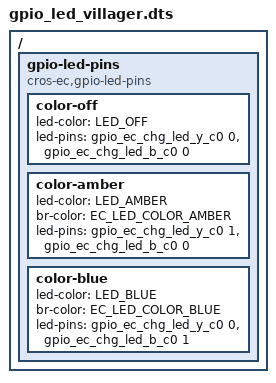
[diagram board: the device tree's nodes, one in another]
/* Copyright 2022 The Chromium OS Authors. All rights reserved.
 * Use of this source code is governed by a BSD-style license that can be
 * found in the LICENSE file.
 */

/ {
	gpio-led-pins {
		compatible = "cros-ec,gpio-led-pins";

		color-off {
			led-color = "LED_OFF";
			led-pins = <&gpio_ec_chg_led_y_c0 0>,
				   <&gpio_ec_chg_led_b_c0 0>;
		};

		color-amber {
			led-color = "LED_AMBER";
			br-color = "EC_LED_COLOR_AMBER";
			led-pins = <&gpio_ec_chg_led_y_c0 1>,
				   <&gpio_ec_chg_led_b_c0 0>;
		};

		color-blue {
			led-color = "LED_BLUE";
			br-color = "EC_LED_COLOR_BLUE";
			led-pins = <&gpio_ec_chg_led_y_c0 0>,
				   <&gpio_ec_chg_led_b_c0 1>;
		};
	};
};
